# DISPC_COMMON register map
Vendor: Texas Instruments
Peripheral module from a debugger description file (folder 66AK2G0x_66AK2G1x).
Registers are 32-bit, access per field, reset values left out (the file's numbers can be read two ways) unless marked. A register's access mark holds for its fields unless they carry their own. Offsets are as the file gives them; lines under a group give offsets from that group; [hi:lo] are bit positions; {n}, {i} and the like mark numbered series; 'fields as' and 'values as' point back to an identical list; <NAME> marks a mode.

## DISPC_COMMON
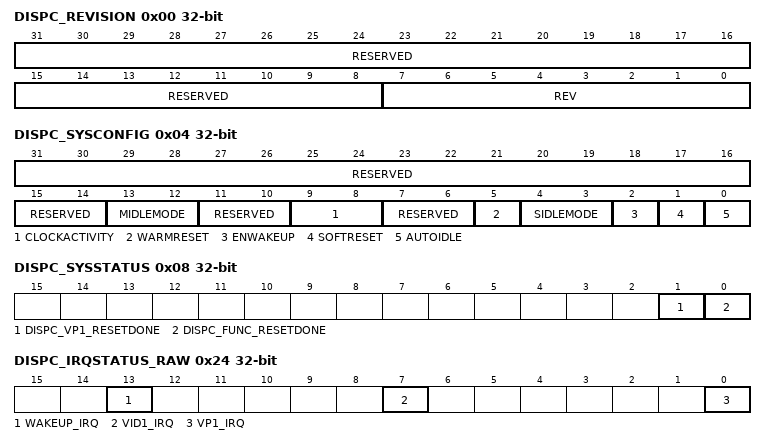
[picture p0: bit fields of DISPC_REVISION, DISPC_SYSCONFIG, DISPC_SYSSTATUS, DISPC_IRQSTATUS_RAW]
0x00 DISPC_REVISION ro
  [31:8] RESERVED — Write 0's for future compatibility. Reads return 0
  [7:0] REV — TI internal data. Identifies revision of peripheral.
0x04 DISPC_SYSCONFIG
  [31:14] RESERVED ro — Write 0's for future compatibility. Reads returns 0
  [13:12] MIDLEMODE rw — Master interface power management, standby/wait control 0h (R/W) = Force-standby.MStandby is only asserted when the module is disabled. MStandby is only asserted when the module is disabled. 1h (R/W) = No-Standby:MStandby is never asserted. 2h (R/W) = Smart-Standby.MStandby is asserted based on the internal activity of the module 3h (R/W) = Reserved
  [11:10] RESERVED ro — Write 0's for future compatibility. Reads returns 0
  [9:8] CLOCKACTIVITY rw — Clocks activity during wake up mode period 0h (R/W) = OCP and Functional clocks can be switched off 1h (R/W) = Functional clocks can be switched off and OCP clocks are mantained during wake up period 2h (R/W) = OCP clocks can be switched off and Functional clocks are maintained during wake up period 3h (R/W) = OCP and Functional clocks are maintained during wake up period
  [7:6] RESERVED ro — Write 0's for future compatibility. Reads returns 0
  [5] WARMRESET rw — Warm reset. Set this bit to 1 triggers a module warm reset. The bit is automatically reset by the hardware. During reads, it always returns 0. The warm reset keep the configuration registers unchanged. 0h (R/W) = Normal mode 1h (R/W) = The warmreset is set
  [4:3] SIDLEMODE rw — Slave interface power management, Idle req/ack control 0h (R/W) = Force-idle.An idle request is acknowledged unconditionally 1h (R/W) = No-idle. An idle request is never acknowledged . 2h (R/W) = Smart-idle. Acknowledgement to an idle request is given based on the internal activity of the module. 3h (R/W) = Reserved
  [2] ENWAKEUP rw — WakeUp feature control. 0h (R/W) = Wakeup is disabled 1h (R/W) = Wakeup is enabled
  [1] SOFTRESET rw — Software reset. Set this bit to 1 to trigger a module reset. The bit is automatically reset by the hardware. During reads, it always returns 0. 0h (R/W) = Normal mode 1h (R/W) = The module is reset
  [0] AUTOIDLE rw — Internal OCP clock gating strategy 0h (R/W) = OCP clock is free-running 1h (R/W) = Automatic OCP clocks gating strategy is applied, based on the OCP interface activity. Automatic functional clock gating is also applied to the functional clock based on the module activity (for instance DISPC_ pipe _ATTRIBUTES.ENABLE)
0x08 DISPC_SYSSTATUS ro
  [1] DISPC_VP1_RESETDONE — Reset status of DISPC VP1 pixel clock domain 0h (R) = Internal module reset is on-going 1h (R) = Reset completed
  [0] DISPC_FUNC_RESETDONE — Reset status of DISPC Functional clock domain 0h (R) = Internal module reset is on-going 1h (R) = Reset completed
0x20 DISPC_IRQ_EOI
  [0] LINE_NUMBER rw — Software End Of Interrupt (EOI) control. Write number of interrupt output. The IP has 1 interrupt compliant with H08. 0h (R/W) = Reads always 0 (no EOI memory)
0x24 DISPC_IRQSTATUS_RAW
  [13] WAKEUP_IRQ rw — Wake-up. 0h (R/W) = No event pending 1h (R/W) = IRQ event pending
  [7] VID1_IRQ rw — VID1 IRQ STATUS register indicates the video pipeline 1 interrupt events 0h (R/W) = No event pending 1h (R/W) = IRQ event pending
  [0] VP1_IRQ rw — VP1 IRQ STATUS register indicates the Video Port 1 interrupt events 0h (R/W) = No event pending 1h (R/W) = IRQ event pending
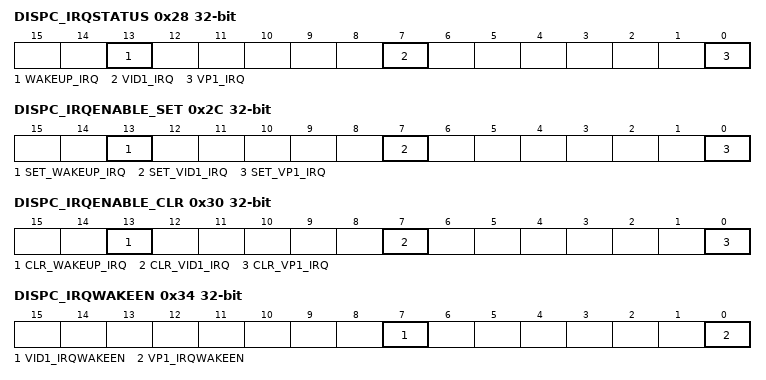
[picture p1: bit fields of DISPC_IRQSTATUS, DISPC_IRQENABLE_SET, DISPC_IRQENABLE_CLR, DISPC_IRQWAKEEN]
0x28 DISPC_IRQSTATUS
  fields as DISPC_IRQSTATUS_RAW
0x2C DISPC_IRQENABLE_SET
  [13] SET_WAKEUP_IRQ rw — Wake Up Mask. 0h (R/W) = interrupt disabled 1h (R/W) = interrupt enabled
  [7] SET_VID1_IRQ rw — VID1 IRQ 0h (R/W) = interrupt disabled 1h (R/W) = interrupt enabled
  [0] SET_VP1_IRQ rw — VP1 IRQ 0h (R/W) = interrupt disabled 1h (R/W) = interrupt enabled
0x30 DISPC_IRQENABLE_CLR
  [13] CLR_WAKEUP_IRQ rw — Wake Up Mask. 0h (R/W) = interrupt disabled 1h (R/W) = interrupt enabled
  [7] CLR_VID1_IRQ rw — VID1 IRQ 0h (R/W) = interrupt disabled 1h (R/W) = interrupt enabled
  [0] CLR_VP1_IRQ rw — VP1 IRQ 0h (R/W) = interrupt disabled 1h (R/W) = interrupt enabled
0x34 DISPC_IRQWAKEEN
  [7] VID1_IRQWAKEEN rw — Wakeupen for VID1 first level interrupt. 0h (R/W) = Swakeup is not generated when this interrupt is asserted in idle mode 1h (R/W) = Swakeup is generated when this interrupt is asserted in idle mode
  [0] VP1_IRQWAKEEN rw — Wakeupen for VP1 first level interrupt. 0h (R/W) = Swakeup is not generated when this interrupt is asserted in idle mode 1h (R/W) = Swakeup is generated when this interrupt is asserted in idle mode
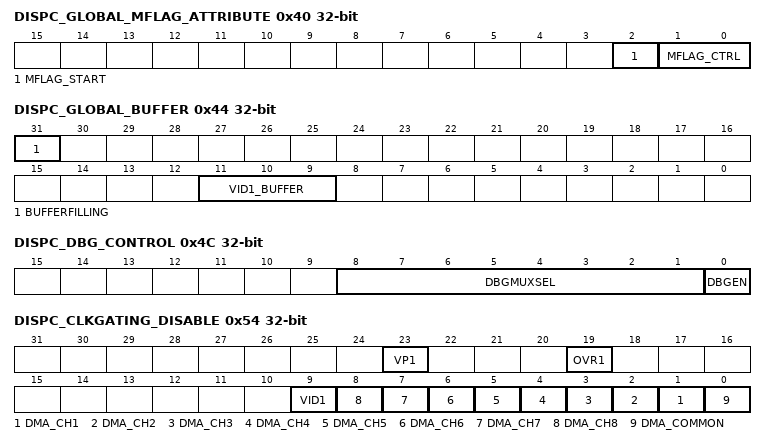
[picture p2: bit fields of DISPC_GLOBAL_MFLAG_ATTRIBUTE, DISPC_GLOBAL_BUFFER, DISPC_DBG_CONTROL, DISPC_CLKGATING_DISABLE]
0x40 DISPC_GLOBAL_MFLAG_ATTRIBUTE
  [2] MFLAG_START rw — 0h (R/W) = reset value, when the DMA buffer is empty at the beginning of the frame, the MFLAG of each pipe is kept at 0 until PRELOAD is reached, then based on MFLAG_CTRL, MFLAG[1:0] are generated and internal logic is arbitrating between pipeline requests 1h (R/W) = Even at the beginning of the frame when the DMA buffer is empty, MFLAG_CTRL is used to determine how MFLAG dedicated to each pipe signal shall be driven
  [1:0] MFLAG_CTRL rw — 0h (R/W) = MFLAG mechanism is disabled: MFLAG[1:0] out band signals are set to 0 1h (R/W) = MFLAG mechanism is enabled: MFLAG[1:0] out band signals are always set to 1 2h (R/W) = MFLAG mechanism is enabled and MFLAG[1:0] out band signals are dynamically set to 0 or 1 depending on the MFLAG rules
0x44 DISPC_GLOBAL_BUFFER
  [31] BUFFERFILLING rw — Controls if the DMA buffers are re-filled only when the LOW threshold is reached or if all DMA buffers are re-filled when at least one of them reaches the LOW threshold. wr: immediate 0h (R/W) = Each DMA buffer is re-filled when it reaches LOW threshold. 1h (R/W) = All DMA buffers are re-filled up to high threshold when at least one of them reaches the LOW threshold. (only active DMA buffers shall be considered and when reaching the end of the frame the DMA buffer goes to empty condition so no need to fill it again).
  [11:9] VID1_BUFFER rw — Video1 DMA buffer allocation to one of the pipelines. By default to video 1 pipeline. 0h (R/W) = DMA buffer is not allocated to a pipeline. 4h (R/W) = DMA buffer allocated to the video1 pipeline. Other values (R/W) = Not supported
0x48 DISPC_BA0_FLIPIMMEDIATE_EN ro
0x4C DISPC_DBG_CONTROL
  [8:1] DBGMUXSEL rw — 0h (R/W) = Select first [31:0] bits of VID-1 debug bus 1h (R/W) = Select first [63:32] bits of VID-1 debug bus 2h (R/W) = Select first [95:64] bits of VID-1 debug bus 3h (R/W) = Select first [127:96] bits of VID-1 debug bus 4h (R/W) = Select first [159:128] bits of VID-1 debug bus 5h (R/W) = Select first [191:160] bits of VID-1 debug bus 6h (R/W) = Select first [223:192] bits of VID-1 debug bus 7h (R/W) = Select first [255:224] bits of VID-1 debug bus 8h to 1Fh (R/W) = Reserved 20h (R/W) = Select VP1 debug bus 21h to FFh(R/W) = Reserved
  [0] DBGEN rw — Enable debug ports 0h (R/W) = DBGDIS 1h (R/W) = DBGEN
0x50 DISPC_DBG_STATUS ro
  [31:0] DBGOUT — Debug bus data selected in
0x54 DISPC_CLKGATING_DISABLE
  [23] VP1 rw — Clock gating control for VP1 0h (R/W) = Clock-Gating is enabled 1h (R/W) = Clock-gating is disabled. Clocks are free running
  [19] OVR1 rw — Clock gating control for OVR1 0h (R/W) = Clock-Gating is enabled 1h (R/W) = Clock-gating is disabled. Clocks are free running
  [9] VID1 rw — Clock gating control for VID1 0h (R/W) = Clock-Gating is enabled 1h (R/W) = Clock-gating is disabled. Clocks are free running
  [n] DMA_CH{n} rw (n=1..8) — Clock gating control for DMA Channel-{n} 0h (R/W) = Clock-Gating is enabled 1h (R/W) = Clock-gating is disabled. Clocks are free running
  [0] DMA_COMMON rw — Clock gating control for DMA_COMMON module 0h (R/W) = Clock-Gating is enabled 1h (R/W) = Clock-gating is disabled. Clocks are free running
